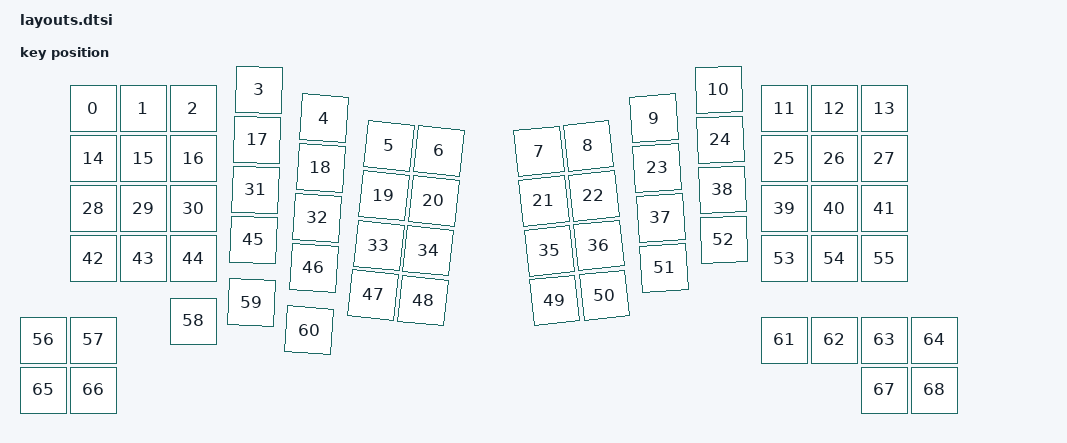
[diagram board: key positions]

#include <physical_layouts.dtsi>
/ {
    physical_layout0: physical_layout0 {
        compatible = "zmk,physical-layout";
        display-name = "Layout";
        keys
            = <&key_physical_attrs 100 100 50 50 0 0 0>
			,<&key_physical_attrs 100 100 150 50 0 0 0>
			,<&key_physical_attrs 100 100 250 50 0 0 0>
			,<&key_physical_attrs 100 100 384 11 200 384 11>
			,<&key_physical_attrs 100 100 516 66 400 516 66>
			,<&key_physical_attrs 100 100 648 120 600 648 120>
			,<&key_physical_attrs 100 100 747 130 600 747 130>
			,<&key_physical_attrs 100 100 937 141 (-600) 937 141>
			,<&key_physical_attrs 100 100 1036 130 (-600) 1036 130>
			,<&key_physical_attrs 100 100 1168 73 (-400) 1168 73>
			,<&key_physical_attrs 100 100 1300 14 (-200) 1300 14>
			,<&key_physical_attrs 100 100 1433 50 0 0 0>
			,<&key_physical_attrs 100 100 1533 50 0 0 0>
			,<&key_physical_attrs 100 100 1633 50 0 0 0>
			,<&key_physical_attrs 100 100 50 150 0 0 0>
			,<&key_physical_attrs 100 100 150 150 0 0 0>
			,<&key_physical_attrs 100 100 250 150 0 0 0>
			,<&key_physical_attrs 100 100 380 111 200 380 111>
			,<&key_physical_attrs 100 100 509 165 400 509 165>
			,<&key_physical_attrs 100 100 637 219 600 637 219>
			,<&key_physical_attrs 100 100 737 230 600 737 230>
			,<&key_physical_attrs 100 100 947 240 (-600) 947 240>
			,<&key_physical_attrs 100 100 1047 230 (-600) 1047 230>
			,<&key_physical_attrs 100 100 1175 172 (-400) 1175 172>
			,<&key_physical_attrs 100 100 1303 114 (-200) 1303 114>
			,<&key_physical_attrs 100 100 1433 150 0 0 0>
			,<&key_physical_attrs 100 100 1533 150 0 0 0>
			,<&key_physical_attrs 100 100 1633 150 0 0 0>
			,<&key_physical_attrs 100 100 50 250 0 0 0>
			,<&key_physical_attrs 100 100 150 250 0 0 0>
			,<&key_physical_attrs 100 100 250 250 0 0 0>
			,<&key_physical_attrs 100 100 377 211 200 377 211>
			,<&key_physical_attrs 100 100 502 265 400 502 265>
			,<&key_physical_attrs 100 100 627 319 600 627 319>
			,<&key_physical_attrs 100 100 726 329 600 726 329>
			,<&key_physical_attrs 100 100 958 340 (-600) 958 340>
			,<&key_physical_attrs 100 100 1057 329 (-600) 1057 329>
			,<&key_physical_attrs 100 100 1182 272 (-400) 1182 272>
			,<&key_physical_attrs 100 100 1307 214 (-200) 1307 214>
			,<&key_physical_attrs 100 100 1433 250 0 0 0>
			,<&key_physical_attrs 100 100 1533 250 0 0 0>
			,<&key_physical_attrs 100 100 1633 250 0 0 0>
			,<&key_physical_attrs 100 100 50 350 0 0 0>
			,<&key_physical_attrs 100 100 150 350 0 0 0>
			,<&key_physical_attrs 100 100 250 350 0 0 0>
			,<&key_physical_attrs 100 100 373 311 200 373 311>
			,<&key_physical_attrs 100 100 495 365 400 495 365>
			,<&key_physical_attrs 100 100 616 418 600 616 418>
			,<&key_physical_attrs 100 100 716 429 600 716 429>
			,<&key_physical_attrs 100 100 968 439 (-600) 968 439>
			,<&key_physical_attrs 100 100 1068 429 (-600) 1068 429>
			,<&key_physical_attrs 100 100 1189 372 (-400) 1189 372>
			,<&key_physical_attrs 100 100 1310 314 (-200) 1310 314>
			,<&key_physical_attrs 100 100 1433 350 0 0 0>
			,<&key_physical_attrs 100 100 1533 350 0 0 0>
			,<&key_physical_attrs 100 100 1633 350 0 0 0>
			,<&key_physical_attrs 100 100 (-50) 513 0 0 0>
			,<&key_physical_attrs 100 100 50 513 0 0 0>
			,<&key_physical_attrs 100 100 250 475 0 0 0>
			,<&key_physical_attrs 100 100 369 436 200 369 436>
			,<&key_physical_attrs 100 100 486 490 400 486 490>
			,<&key_physical_attrs 100 100 1433 513 0 0 0>
			,<&key_physical_attrs 100 100 1532 513 0 0 0>
			,<&key_physical_attrs 100 100 1633 513 0 0 0>
			,<&key_physical_attrs 100 100 1733 513 0 0 0>
			,<&key_physical_attrs 100 100 (-50) 613 0 0 0>
			,<&key_physical_attrs 100 100 50 613 0 0 0>
			,<&key_physical_attrs 100 100 1633 613 0 0 0>
			,<&key_physical_attrs 100 100 1733 613 0 0 0>
            ;
    };
};
    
